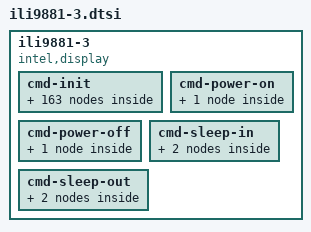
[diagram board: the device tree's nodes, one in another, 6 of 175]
	ili9881-3 {
		compatible = "intel,display";
		intel,display-resolution= <720 1280>;
		intel,display-dpi= <293 293>;

		/* MIPI-DSI video mode settings */
		intel,display-vid-hfp-hs-bytes = <80>;
		intel,display-vid-hbp-hs-bytes = <100>;
		intel,display-vid-hsa-hs-bytes = <60>;
		intel,display-vid-vfp-lines = <18>;
		intel,display-vid-vbp-lines = <18>;
		intel,display-vid-vsa-lines = <8>;

		intel,display-vid-mode = "burst";
		intel,display-vid-id = <0>;
		intel,display-vid-pixel = "24packed";

		intel,display-reset = <1 1 0 10 1 120>;

		cmd-init {
			cmd_page7 {
				intel,cmd-type = <0x39>;
				intel,cmd-data = <0xFF 0x98 0x81 0x07>;
				intel,cmd-lp = <1>;
			};
			gip1_1 {
				intel,cmd-type = <0x15>;
				intel,cmd-data = <0x03 0x20>;
				intel,cmd-lp = <1>;
			};
			gip1_2 {
				intel,cmd-type = <0x15>;
				intel,cmd-data = <0x04 0x0A>;
				intel,cmd-lp = <1>;
			};
			gip1_3 {
				intel,cmd-type = <0x15>;
				intel,cmd-data = <0x05 0x60>;
				intel,cmd-lp = <1>;
			};
			gip1_4 {
				intel,cmd-type = <0x15>;
				intel,cmd-data = <0x06 0x0F>;
				intel,cmd-lp = <1>;
			};
			gip1_5 {
				intel,cmd-type = <0x15>;
				intel,cmd-data = <0x07 0x00>;
				intel,cmd-lp = <1>;
			};
			gip1_6 {
				intel,cmd-type = <0x15>;
				intel,cmd-data = <0x08 0x00>;
				intel,cmd-lp = <1>;
			};
			gip1_7 {
				intel,cmd-type = <0x15>;
				intel,cmd-data = <0x09 0x00>;
				intel,cmd-lp = <1>;
			};
			gip1_8 {
				intel,cmd-type = <0x15>;
				intel,cmd-data = <0x0A 0x01>;
				intel,cmd-lp = <1>;
			};
			gip1_9 {
				intel,cmd-type = <0x15>;
				intel,cmd-data = <0x0B 0x01>;
				intel,cmd-lp = <1>;
			};
			gip1_10 {
				intel,cmd-type = <0x15>;
				intel,cmd-data = <0x0C 0x01>;
				intel,cmd-lp = <1>;
			};
			gip1_11 {
				intel,cmd-type = <0x15>;
				intel,cmd-data = <0x0D 0x01>;
				intel,cmd-lp = <1>;
			};
			gip1_12 {
				intel,cmd-type = <0x15>;
				intel,cmd-data = <0x0E 0x01>;
				intel,cmd-lp = <1>;
			};
			gip1_13 {
				intel,cmd-type = <0x15>;
				intel,cmd-data = <0x0F 0x01>;
				intel,cmd-lp = <1>;
			};
			gip_14 {
				intel,cmd-type = <0x15>;
				intel,cmd-data = <0x10 0x40>;
				intel,cmd-lp = <1>;
			};
			gip1_15 {
				intel,cmd-type = <0x15>;
				intel,cmd-data = <0x11 0x06>;
				intel,cmd-lp = <1>;
			};
			gip1_16 {
				intel,cmd-type = <0x15>;
				intel,cmd-data = <0x12 0x01>;
				intel,cmd-lp = <1>;
			};
			gip1_17 {
				intel,cmd-type = <0x15>;
				intel,cmd-data = <0x13 0x00>;
				intel,cmd-lp = <1>;
			};
			gip1_18 {
				intel,cmd-type = <0x15>;
				intel,cmd-data = <0x14 0x00>;
				intel,cmd-lp = <1>;
			};
			gip1_19 {
				intel,cmd-type = <0x15>;
				intel,cmd-data = <0x15 0x00>;
				intel,cmd-lp = <1>;
			};
			gip1_20 {
				intel,cmd-type = <0x15>;
				intel,cmd-data = <0x16 0x01>;
				intel,cmd-lp = <1>;
			};
			gip1_21 {
				intel,cmd-type = <0x15>;
				intel,cmd-data = <0x17 0x01>;
				intel,cmd-lp = <1>;
			};
			gip1_22 {
				intel,cmd-type = <0x15>;
				intel,cmd-data = <0x18 0x00>;
				intel,cmd-lp = <1>;
			};
			gip1_23 {
				intel,cmd-type = <0x15>;
				intel,cmd-data = <0x19 0x00>;
				intel,cmd-lp = <1>;
			};
			gip1_24 {
				intel,cmd-type = <0x15>;
				intel,cmd-data = <0x1A 0x00>;
				intel,cmd-lp = <1>;
			};
			gip1_25 {
				intel,cmd-type = <0x15>;
				intel,cmd-data = <0x1B 0xD0>;
				intel,cmd-lp = <1>;
			};
			gip1_26 {
				intel,cmd-type = <0x15>;
				intel,cmd-data = <0x1C 0xBB>;
				intel,cmd-lp = <1>;
			};
			gip1_27 {
				intel,cmd-type = <0x15>;
				intel,cmd-data = <0x1D 0x0B>;
				intel,cmd-lp = <1>;
			};
			gip1_28 {
				intel,cmd-type = <0x15>;
				intel,cmd-data = <0x1E 0x01>;
				intel,cmd-lp = <1>;
			};
			gip1_29 {
				intel,cmd-type = <0x15>;
				intel,cmd-data = <0x1F 0x00>;
				intel,cmd-lp = <1>;
			};
			gip1_30 {
				intel,cmd-type = <0x15>;
				intel,cmd-data = <0x20 0x00>;
				intel,cmd-lp = <1>;
			};
			gip1_31 {
				intel,cmd-type = <0x15>;
				intel,cmd-data = <0x21 0x00>;
				intel,cmd-lp = <1>;
			};
			gip1_32 {
				intel,cmd-type = <0x15>;
				intel,cmd-data = <0x22 0x00>;
				intel,cmd-lp = <1>;
			};
			gip1_33 {
				intel,cmd-type = <0x15>;
				intel,cmd-data = <0x23 0xC0>;
				intel,cmd-lp = <1>;
			};
			gip1_34 {
				intel,cmd-type = <0x15>;
				intel,cmd-data = <0x24 0x30>;
				intel,cmd-lp = <1>;
			};
			gip1_35 {
				intel,cmd-type = <0x15>;
				intel,cmd-data = <0x25 0x00>;
				intel,cmd-lp = <1>;
			};
			gip1_36 {
				intel,cmd-type = <0x15>;
				intel,cmd-data = <0x26 0x00>;
				intel,cmd-lp = <1>;
			};
			gip1_37 {
				intel,cmd-type = <0x15>;
				intel,cmd-data = <0x27 0x03>;
				intel,cmd-lp = <1>;
			};
			gip2_1 {
				intel,cmd-type = <0x15>;
				intel,cmd-data = <0x30 0x01>;
				intel,cmd-lp = <1>;
			};
			gip2_2 {
				intel,cmd-type = <0x15>;
				intel,cmd-data = <0x31 0x23>;
				intel,cmd-lp = <1>;
			};
			gip2_3 {
				intel,cmd-type = <0x15>;
				intel,cmd-data = <0x32 0x45>;
				intel,cmd-lp = <1>;
			};
			gip2_4 {
				intel,cmd-type = <0x15>;
				intel,cmd-data = <0x33 0x67>;
				intel,cmd-lp = <1>;
			};
			gip2_5 {
				intel,cmd-type = <0x15>;
				intel,cmd-data = <0x34 0x89>;
				intel,cmd-lp = <1>;
			};
			gip2_6 {
				intel,cmd-type = <0x15>;
				intel,cmd-data = <0x35 0xAB>;
				intel,cmd-lp = <1>;
			};
			gip2_7 {
				intel,cmd-type = <0x15>;
				intel,cmd-data = <0x36 0x01>;
				intel,cmd-lp = <1>;
			};
			gip2_8 {
				intel,cmd-type = <0x15>;
				intel,cmd-data = <0x37 0x23>;
				intel,cmd-lp = <1>;
			};
			gip2_9 {
				intel,cmd-type = <0x15>;
				intel,cmd-data = <0x38 0x45>;
				intel,cmd-lp = <1>;
			};
			gip2_10 {
				intel,cmd-type = <0x15>;
				intel,cmd-data = <0x39 0x67>;
				intel,cmd-lp = <1>;
			};
			gip2_11 {
				intel,cmd-type = <0x15>;
				intel,cmd-data = <0x3A 0x89>;
				intel,cmd-lp = <1>;
			};
			gip2_12 {
				intel,cmd-type = <0x15>;
				intel,cmd-data = <0x3B 0xAB>;
				intel,cmd-lp = <1>;
			};
			gip2_13 {
				intel,cmd-type = <0x15>;
				intel,cmd-data = <0x3C 0xCD>;
				intel,cmd-lp = <1>;
			};
			gip2_14 {
				intel,cmd-type = <0x15>;
				intel,cmd-data = <0x3D 0xEF>;
				intel,cmd-lp = <1>;
			};
			gip3_1 {
				intel,cmd-type = <0x15>;
				intel,cmd-data = <0x50 0x11>;
				intel,cmd-lp = <1>;
			};
			gip3_2 {
				intel,cmd-type = <0x15>;
				intel,cmd-data = <0x51 0x0D>;
				intel,cmd-lp = <1>;
			};
			gip3_3 {
				intel,cmd-type = <0x15>;
				intel,cmd-data = <0x52 0x0C>;
				intel,cmd-lp = <1>;
			};
			gip3_4 {
				intel,cmd-type = <0x15>;
				intel,cmd-data = <0x53 0x0F>;
				intel,cmd-lp = <1>;
			};
			gip3_5 {
				intel,cmd-type = <0x15>;
				intel,cmd-data = <0x54 0x0E>;
				intel,cmd-lp = <1>;
			};
			gip3_6 {
				intel,cmd-type = <0x15>;
				intel,cmd-data = <0x55 0x06>;
				intel,cmd-lp = <1>;
			};
			gip3_7 {
				intel,cmd-type = <0x15>;
				intel,cmd-data = <0x56 0x07>;
				intel,cmd-lp = <1>;
			};
			gip3_8 {
				intel,cmd-type = <0x15>;
				intel,cmd-data = <0x57 0x02>;
				intel,cmd-lp = <1>;
			};
			gip3_9 {
				intel,cmd-type = <0x15>;
				intel,cmd-data = <0x58 0x02>;
				intel,cmd-lp = <1>;
			};
			gip3_10 {
				intel,cmd-type = <0x15>;
				intel,cmd-data = <0x59 0x02>;
				intel,cmd-lp = <1>;
			};
			gip3_11 {
				intel,cmd-type = <0x15>;
				intel,cmd-data = <0x5A 0x02>;
				intel,cmd-lp = <1>;
			};
			gip3_12 {
				intel,cmd-type = <0x15>;
				intel,cmd-data = <0x5B 0x02>;
				intel,cmd-lp = <1>;
			};
			gip3_13 {
				intel,cmd-type = <0x15>;
				intel,cmd-data = <0x5C 0x02>;
				intel,cmd-lp = <1>;
			};
			gip3_14 {
				intel,cmd-type = <0x15>;
				intel,cmd-data = <0x5D 0x02>;
				intel,cmd-lp = <1>;
			};
			gip3_15 {
				intel,cmd-type = <0x15>;
				intel,cmd-data = <0x5E 0x02>;
				intel,cmd-lp = <1>;
			};
			gip3_16 {
				intel,cmd-type = <0x15>;
				intel,cmd-data = <0x5F 0x02>;
				intel,cmd-lp = <1>;
			};
			gip3_17 {
				intel,cmd-type = <0x15>;
				intel,cmd-data = <0x60 0x02>;
				intel,cmd-lp = <1>;
			};
			gip3_18 {
				intel,cmd-type = <0x15>;
				intel,cmd-data = <0x61 0x02>;
				intel,cmd-lp = <1>;
			};
			gip3_19 {
				intel,cmd-type = <0x15>;
				intel,cmd-data = <0x62 0x02>;
				intel,cmd-lp = <1>;
			};
			gip3_20 {
				intel,cmd-type = <0x15>;
				intel,cmd-data = <0x63 0x02>;
				intel,cmd-lp = <1>;
			};
			gip3_21 {
				intel,cmd-type = <0x15>;
				intel,cmd-data = <0x64 0x08>;
				intel,cmd-lp = <1>;
			};
			gip3_22 {
				intel,cmd-type = <0x15>;
				intel,cmd-data = <0x65 0x00>;
				intel,cmd-lp = <1>;
			};
			gip3_23 {
				intel,cmd-type = <0x15>;
				intel,cmd-data = <0x66 0x01>;
				intel,cmd-lp = <1>;
			};
			gip3_24 {
				intel,cmd-type = <0x15>;
				intel,cmd-data = <0x67 0x0D>;
				intel,cmd-lp = <1>;
			};
			gip3_25 {
				intel,cmd-type = <0x15>;
				intel,cmd-data = <0x68 0x0C>;
				intel,cmd-lp = <1>;
			};
			gip3_26 {
				intel,cmd-type = <0x15>;
				intel,cmd-data = <0x69 0x0F>;
				intel,cmd-lp = <1>;
			};
			gip3_27 {
				intel,cmd-type = <0x15>;
				intel,cmd-data = <0x6A 0x0E>;
				intel,cmd-lp = <1>;
			};
			gip3_28 {
				intel,cmd-type = <0x15>;
				intel,cmd-data = <0x6B 0x06>;
				intel,cmd-lp = <1>;
			};
			gip3_29 {
				intel,cmd-type = <0x15>;
				intel,cmd-data = <0x6C 0x07>;
				intel,cmd-lp = <1>;
			};
			gip3_30 {
				intel,cmd-type = <0x15>;
				intel,cmd-data = <0x6D 0x02>;
				intel,cmd-lp = <1>;
			};
			gip3_31 {
				intel,cmd-type = <0x15>;
				intel,cmd-data = <0x6E 0x02>;
				intel,cmd-lp = <1>;
			};
			gip3_32 {
				intel,cmd-type = <0x15>;
				intel,cmd-data = <0x6F 0x02>;
				intel,cmd-lp = <1>;
			};
			gip3_33 {
				intel,cmd-type = <0x15>;
				intel,cmd-data = <0x70 0x02>;
				intel,cmd-lp = <1>;
			};
			gip3_34 {
				intel,cmd-type = <0x15>;
				intel,cmd-data = <0x71 0x02>;
				intel,cmd-lp = <1>;
			};
			gip3_35 {
				intel,cmd-type = <0x15>;
				intel,cmd-data = <0x72 0x02>;
				intel,cmd-lp = <1>;
			};
			gip3_36 {
				intel,cmd-type = <0x15>;
				intel,cmd-data = <0x73 0x02>;
				intel,cmd-lp = <1>;
			};
			gip3_37 {
				intel,cmd-type = <0x15>;
				intel,cmd-data = <0x74 0x02>;
				intel,cmd-lp = <1>;
			};
			gip3_38 {
				intel,cmd-type = <0x15>;
				intel,cmd-data = <0x75 0x02>;
				intel,cmd-lp = <1>;
			};
			gip3_39 {
				intel,cmd-type = <0x15>;
				intel,cmd-data = <0x76 0x02>;
				intel,cmd-lp = <1>;
			};
			gip3_40 {
				intel,cmd-type = <0x15>;
				intel,cmd-data = <0x77 0x02>;
				intel,cmd-lp = <1>;
			};
			gip3_41 {
				intel,cmd-type = <0x15>;
				intel,cmd-data = <0x78 0x02>;
				intel,cmd-lp = <1>;
			};
			gip3_42 {
				intel,cmd-type = <0x15>;
				intel,cmd-data = <0x79 0x02>;
				intel,cmd-lp = <1>;
			};
			gip3_43 {
				intel,cmd-type = <0x15>;
				intel,cmd-data = <0x7A 0x08>;
				intel,cmd-lp = <1>;
			};
			gip3_44 {
				intel,cmd-type = <0x15>;
				intel,cmd-data = <0x7B 0x00>;
				intel,cmd-lp = <1>;
			};
			gip3_45 {
				intel,cmd-type = <0x15>;
				intel,cmd-data = <0x7C 0x01>;
				intel,cmd-lp = <1>;
			};
			cmd_page8 {
				intel,cmd-type = <0x39>;
				intel,cmd-data = <0xFF 0x98 0x81 0x08>;
				intel,cmd-lp = <1>;
			};
			vgh-pumping-ratio-3x {
				intel,cmd-type = <0x15>;
				intel,cmd-data = <0x76 0xB4>;
				intel,cmd-lp = <1>;
			};
			vgl-pumping-ratio-2.5x {
				intel,cmd-type = <0x15>;
				intel,cmd-data = <0x78 0x04>;
				intel,cmd-lp = <1>;
			};
			vgh-clamp-15v {
				intel,cmd-type = <0x15>;
				intel,cmd-data = <0x74 0x2B>;
				intel,cmd-lp = <1>;
			};
			vgl-clamp-10v {
				intel,cmd-type = <0x15>;
				intel,cmd-data = <0x8E 0x15>;
				intel,cmd-lp = <1>;
			};
			power-saving {
				intel,cmd-type = <0x15>;
				intel,cmd-data = <0x40 0x01>;
				intel,cmd-lp = <1>;
			};
			power-mode-2a {
				intel,cmd-type = <0x15>;
				intel,cmd-data = <0x7B 0x04>;
				intel,cmd-lp = <1>;
			};
			vcore-1.6v {
				intel,cmd-type = <0x15>;
				intel,cmd-data = <0x72 0x25>;
				intel,cmd-lp = <1>;
			};
			per-ehance-1 {
				intel,cmd-type = <0x15>;
				intel,cmd-data = <0x87 0x3A>;
				intel,cmd-lp = <1>;
			};
			vglo1-hi-z {
				intel,cmd-type = <0x15>;
				intel,cmd-data = <0x6C 0x05>;
				intel,cmd-lp = <1>;
			};
			per-enhance-2 {
				intel,cmd-type = <0x15>;
				intel,cmd-data = <0x49 0x10>;
				intel,cmd-lp = <1>;
			};
			per-enhance-3 {
				intel,cmd-type = <0x15>;
				intel,cmd-data = <0x2D 0x80>;
				intel,cmd-lp = <1>;
			};
			cmd_page1 {
				intel,cmd-type = <0x39>;
				intel,cmd-data = <0xFF 0x98 0x81 0x01>;
				intel,cmd-lp = <1>;
			};
			bgr-ss {
				intel,cmd-type = <0x15>;
				intel,cmd-data = <0x22 0x0A>;
				intel,cmd-lp = <1>;
			};
			column-inver {
				intel,cmd-type = <0x15>;
				intel,cmd-data = <0x31 0x00>;
				intel,cmd-lp = <1>;
			};
			vcom1-forward {
				intel,cmd-type = <0x15>;
				intel,cmd-data = <0x53 0x80>;
				intel,cmd-lp = <1>;
			};
			vcom2-backward {
				intel,cmd-type = <0x15>;
				intel,cmd-data = <0x55 0x92>;
				intel,cmd-lp = <1>;
			};
			vreg1out-4.5v {
				intel,cmd-type = <0x15>;
				intel,cmd-data = <0x50 0x95>;
				intel,cmd-lp = <1>;
			};
			vreg2out-4.5v {
				intel,cmd-type = <0x15>;
				intel,cmd-data = <0x51 0x95>;
				intel,cmd-lp = <1>;
			};
			vp255-gamma-p {
				intel,cmd-type = <0x15>;
				intel,cmd-data = <0xA0 0x08>;
				intel,cmd-lp = <1>;
			};
			vp251 {
				intel,cmd-type = <0x15>;
				intel,cmd-data = <0xA1 0x27>;
				intel,cmd-lp = <1>;
			};
			vp247 {
				intel,cmd-type = <0x15>;
				intel,cmd-data = <0xA2 0x3A>;
				intel,cmd-lp = <1>;
			};
			vp243 {
				intel,cmd-type = <0x15>;
				intel,cmd-data = <0xA3 0x17>;
				intel,cmd-lp = <1>;
			};
			vp239 {
				intel,cmd-type = <0x15>;
				intel,cmd-data = <0xA4 0x1B>;
				intel,cmd-lp = <1>;
			};
			vp231 {
				intel,cmd-type = <0x15>;
				intel,cmd-data = <0xA5 0x2D>;
				intel,cmd-lp = <1>;
			};
			vp219 {
				intel,cmd-type = <0x15>;
				intel,cmd-data = <0xA6 0x21>;
				intel,cmd-lp = <1>;
			};
			vp203 {
				intel,cmd-type = <0x15>;
				intel,cmd-data = <0xA7 0x21>;
				intel,cmd-lp = <1>;
			};
			vp175 {
				intel,cmd-type = <0x15>;
				intel,cmd-data = <0xA8 0xBD>;
				intel,cmd-lp = <1>;
			};
			vp144 {
				intel,cmd-type = <0x15>;
				intel,cmd-data = <0xA9 0x1C>;
				intel,cmd-lp = <1>;
			};
			vp111 {
				intel,cmd-type = <0x15>;
				intel,cmd-data = <0xAA 0x28>;
				intel,cmd-lp = <1>;
			};
			vp80 {
				intel,cmd-type = <0x15>;
				intel,cmd-data = <0xAB 0xA4>;
				intel,cmd-lp = <1>;
			};
			vp52 {
				intel,cmd-type = <0x15>;
				intel,cmd-data = <0xAC 0x1B>;
				intel,cmd-lp = <1>;
			};
			vp36 {
				intel,cmd-type = <0x15>;
				intel,cmd-data = <0xAD 0x16>;
				intel,cmd-lp = <1>;
			};
			vp24 {
				intel,cmd-type = <0x15>;
				intel,cmd-data = <0xAE 0x4A>;
				intel,cmd-lp = <1>;
			};
			vp16 {
				intel,cmd-type = <0x15>;
				intel,cmd-data = <0xAF 0x1C>;
				intel,cmd-lp = <1>;
			};
			vp12 {
				intel,cmd-type = <0x15>;
				intel,cmd-data = <0xB0 0x21>;
				intel,cmd-lp = <1>;
			};
			vp8 {
				intel,cmd-type = <0x15>;
				intel,cmd-data = <0xB1 0x5A>;
				intel,cmd-lp = <1>;
			};
			vp4 {
				intel,cmd-type = <0x15>;
				intel,cmd-data = <0xB2 0x68>;
				intel,cmd-lp = <1>;
			};
			vp0 {
				intel,cmd-type = <0x15>;
				intel,cmd-data = <0xB3 0x39>;
				intel,cmd-lp = <1>;
			};
			vn255-gamma-n {
				intel,cmd-type = <0x15>;
				intel,cmd-data = <0xC0 0x08>;
				intel,cmd-lp = <1>;
			};
			vn251 {
				intel,cmd-type = <0x15>;
				intel,cmd-data = <0xC1 0x2B>;
				intel,cmd-lp = <1>;
			};
			vn247 {
				intel,cmd-type = <0x15>;
				intel,cmd-data = <0xC2 0x3A>;
				intel,cmd-lp = <1>;
			};
			vn243 {
				intel,cmd-type = <0x15>;
				intel,cmd-data = <0xC3 0x17>;
				intel,cmd-lp = <1>;
			};
			vn239 {
				intel,cmd-type = <0x15>;
				intel,cmd-data = <0xC4 0x1B>;
				intel,cmd-lp = <1>;
			};
			vn231 {
				intel,cmd-type = <0x15>;
				intel,cmd-data = <0xC5 0x2D>;
				intel,cmd-lp = <1>;
			};
			vn219 {
				intel,cmd-type = <0x15>;
				intel,cmd-data = <0xC6 0x21>;
				intel,cmd-lp = <1>;
			};
			vn203 {
				intel,cmd-type = <0x15>;
				intel,cmd-data = <0xC7 0x21>;
				intel,cmd-lp = <1>;
			};
			vn175 {
				intel,cmd-type = <0x15>;
				intel,cmd-data = <0xC8 0xB5>;
				intel,cmd-lp = <1>;
			};
			vn144 {
				intel,cmd-type = <0x15>;
				intel,cmd-data = <0xC9 0x21>;
				intel,cmd-lp = <1>;
			};
			vn111 {
				intel,cmd-type = <0x15>;
				intel,cmd-data = <0xCA 0x2B>;
				intel,cmd-lp = <1>;
			};
			vn80 {
				intel,cmd-type = <0x15>;
				intel,cmd-data = <0xCB 0xA8>;
				intel,cmd-lp = <1>;
			};
			vn52 {
				intel,cmd-type = <0x15>;
				intel,cmd-data = <0xCC 0x21>;
				intel,cmd-lp = <1>;
			};
			vn36 {
				intel,cmd-type = <0x15>;
				intel,cmd-data = <0xCD 0x20>;
				intel,cmd-lp = <1>;
			};
			vn24 {
				intel,cmd-type = <0x15>;
				intel,cmd-data = <0xCE 0x56>;
				intel,cmd-lp = <1>;
			};
			vn16 {
				intel,cmd-type = <0x15>;
				intel,cmd-data = <0xCF 0x2D>;
				intel,cmd-lp = <1>;
			};
			vn12 {
				intel,cmd-type = <0x15>;
				intel,cmd-data = <0xD0 0x30>;
				intel,cmd-lp = <1>;
			};
			vn8 {
				intel,cmd-type = <0x15>;
				intel,cmd-data = <0xD1 0x5A>;
				intel,cmd-lp = <1>;
			};
			vn4 {
				intel,cmd-type = <0x15>;
				intel,cmd-data = <0xD2 0x68>;
				intel,cmd-lp = <1>;
			};
			vn0 {
				intel,cmd-type = <0x15>;
				intel,cmd-data = <0xD3 0x39>;
				intel,cmd-lp = <1>;
			};
			cmd_page0 {
				intel,cmd-type = <0x39>;
				intel,cmd-data = <0xFF 0x98 0x81 0x00>;
				intel,cmd-lp = <1>;
			};
			set-CABC{
				intel,cmd-type = <0x15>;
				intel,cmd-data = <0x55 0x01>;
				intel,cmd-lp = <1>;
			};
			set-backlight{
				intel,cmd-type = <0x15>;
				intel,cmd-data = <0x53 0x2C>;
				intel,cmd-lp = <1>;
			};
			set-brightness{
				intel,cmd-type = <0x15>;
				intel,cmd-data = <0x51 0xFF>;
				intel,cmd-lp = <1>;
			};
			set_bgr {
				intel,cmd-type = <0x15>;
				intel,cmd-data = <0x36 0x08>;
				intel,cmd-lp = <1>;
			};
			sleep-out{
				intel,cmd-type = <0x15>;
				intel,cmd-data = <0x11 0x00>;
				intel,cmd-lp = <1>;
				intel,cmd-delay = <120>;
			};
			display-on{
				intel,cmd-type = <0x15>;
				intel,cmd-data = <0x29 00>;
				intel,cmd-lp = <1>;
			};
		};

		cmd-power-on {
			display-on{
				intel,cmd-type = <0x15>;
				intel,cmd-data = <0x29 0x00>;
				intel,cmd-lp = <1>;
			};
		};

		cmd-power-off {
			display-off{
				intel,cmd-type = <0x15>;
				intel,cmd-data = <0x28 0x00>;
				intel,cmd-lp = <1>;
				intel,cmd-delay = <10>;
			};
		};

		cmd-sleep-in {
			display-off{
				intel,cmd-type = <0x15>;
				intel,cmd-data = <0x28 0x00>;
				intel,cmd-lp = <1>;
				intel,cmd-delay = <10>;
			};
			sleep-in{
				intel,cmd-type = <0x15>;
				intel,cmd-data = <0x10 0x00>;
				intel,cmd-lp = <1>;
				intel,cmd-delay = <120>;
			};
		};

		cmd-sleep-out {
			sleep-out{
				intel,cmd-type = <0x15>;
				intel,cmd-data = <0x11 0x00>;
				intel,cmd-lp = <1>;
				intel,cmd-delay = <120>;
			};
			display-on{
				intel,cmd-type = <0x15>;
				intel,cmd-data = <0x29 00>;
				intel,cmd-lp = <1>;
			};
		};
	};
